AUTOSAR XML (schema 00049)
package /Application/DltConfig
  dlt log channel to process mapping DltLogChannelToProcessMapping_IntelligentWiper_TO_IntelligentWiper: dlt-log-channel=IntelligentWiper, process=IntelligentWiper
package /Application/Executable
  executable IntelligentWiper: category=APPLICATION_LEVEL, logging-behavior=USES-LOGGING, reporting-behavior=REPORTS-EXECUTION-STATE, version=1.0.0
    root sw component prototype AA: application-type=IntelligentWiper
package /Application/Manifest
  service instance to port prototype mapping IntelligentWiper_AA_RPort_SubscriptionManagement: port-prototype=AA.RPort_SubscriptionManagement, service-instance=EEVP_IntelligentWiper_Consumer_SubscriptionManagement
  service instance to port prototype mapping IntelligentWiper_AA_RPort_VehicleInfo: port-prototype=AA.RPort_VehicleInfo, service-instance=EEVP_IntelligentWiper_Consumer_SoaVehicleInfo
  service instance to port prototype mapping IntelligentWiper_AA_RPort_Wiper: port-prototype=AA.RPort_Wiper, service-instance=EEVP_IntelligentWiper_Consumer_SoaWiper
package /Application/Process
  process IntelligentWiper: executable=IntelligentWiper, state-dependent-startup-config{function-group-state=[SFG02.On, SFG02.Verify], resource-group=DefaultResourceGroup, startup-config=DefaultStartupConfig}
    process state machine IntelligentWiper: type=ProcessState
package /Application/SwComponent
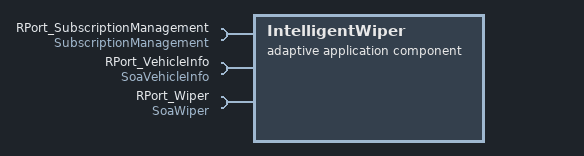
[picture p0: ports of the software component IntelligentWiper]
  adaptive application sw component type IntelligentWiper
    require port RPort_SubscriptionManagement: required-interface=SubscriptionManagement
    require port RPort_VehicleInfo: required-interface=SoaVehicleInfo
    require port RPort_Wiper: required-interface=SoaWiper
